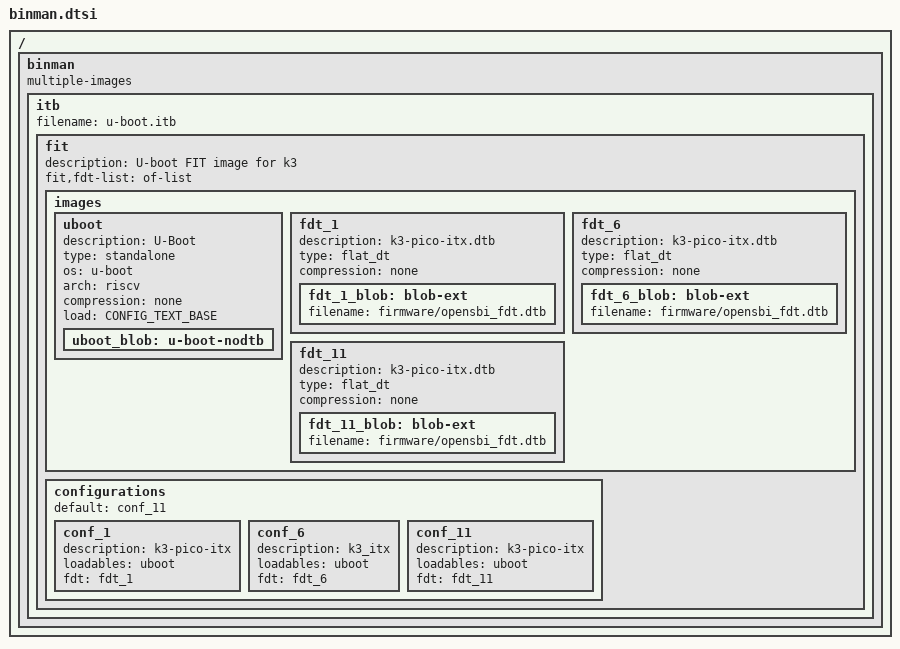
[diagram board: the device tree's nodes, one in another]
// SPDX-License-Identifier: GPL-2.0+
/*
 * Copyright (C) 2021, Bin Meng <bmeng.cn@gmail.com>
 */

#include <config.h>

/ {
	binman: binman {
		multiple-images;
	};
};

&binman {
	itb {

#ifndef CONFIG_SPL_LOAD_FIT_OPENSBI_OS_BOOT
		filename = "u-boot.itb";
#else
		filename = "linux.itb";
#endif

		fit {
			description = "U-boot FIT image for k3";
			#address-cells = <2>;
			fit,fdt-list = "of-list";

			images {
				uboot {
					description = "U-Boot";
					type = "standalone";
					os = "u-boot";
					arch = "riscv";
					compression = "none";
					load = /bits/ 64 <CONFIG_TEXT_BASE>;

					uboot_blob: u-boot-nodtb {
					};
				};

				fdt_1 {
					description = "k3-pico-itx.dtb";
					type = "flat_dt";
					compression = "none";

					fdt_1_blob: blob-ext {
						filename = "firmware/opensbi_fdt.dtb";
					};
				};

				fdt_6 {
					description = "k3-pico-itx.dtb";
					type = "flat_dt";
					compression = "none";

					fdt_6_blob: blob-ext {
						filename = "firmware/opensbi_fdt.dtb";
					};
				};

				fdt_11 {
					description = "k3-pico-itx.dtb";
					type = "flat_dt";
					compression = "none";

					fdt_11_blob: blob-ext {
						filename = "firmware/opensbi_fdt.dtb";
					};
				};
			};

			configurations {
				default = "conf_11";

				conf_1 {
					description = "k3-pico-itx";
					loadables = "uboot";
					fdt = "fdt_1";
				};

				conf_6 {
					description = "k3_itx";
					loadables = "uboot";
					fdt = "fdt_6";
				};

				conf_11 {
					description = "k3-pico-itx";
					loadables = "uboot";
					fdt = "fdt_11";
				};
			};
		};
	};
};
